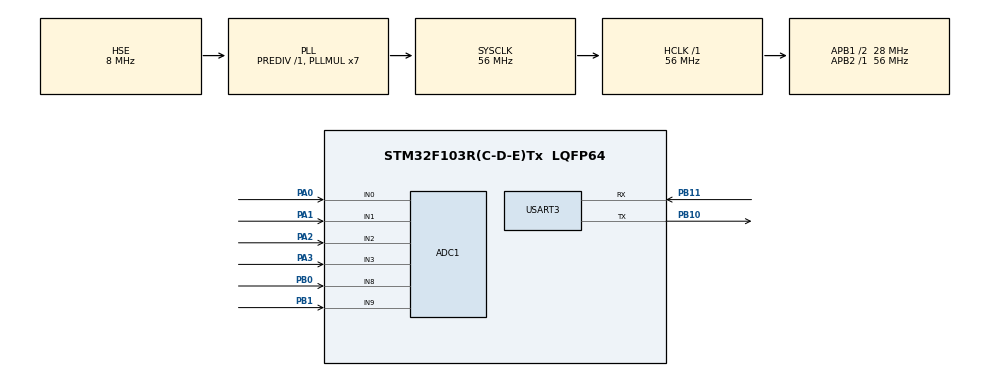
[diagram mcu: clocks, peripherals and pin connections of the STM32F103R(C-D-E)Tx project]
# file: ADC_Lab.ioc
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ADC1.Channel-0\#ChannelRegularConversion=ADC_CHANNEL_0
ADC1.ContinuousConvMode=ENABLE
ADC1.EnableAnalogWatchDog=false
ADC1.ExternalTrigConv=ADC_EXTERNALTRIGCONV_T3_TRGO
ADC1.NbrOfConversion=1
ADC1.NbrOfConversionFlag=1
ADC1.Rank-0\#ChannelRegularConversion=1
ADC1.SamplingTime-0\#ChannelRegularConversion=ADC_SAMPLETIME_1CYCLE_5
ADC1.master=1
Dma.ADC1.0.Direction=DMA_PERIPH_TO_MEMORY
Dma.ADC1.0.Instance=DMA1_Channel1
Dma.ADC1.0.MemDataAlignment=DMA_MDATAALIGN_WORD
Dma.ADC1.0.MemInc=DMA_MINC_ENABLE
Dma.ADC1.0.Mode=DMA_CIRCULAR
Dma.ADC1.0.PeriphDataAlignment=DMA_PDATAALIGN_WORD
Dma.ADC1.0.PeriphInc=DMA_PINC_DISABLE
Dma.ADC1.0.Priority=DMA_PRIORITY_LOW
Dma.Request0=ADC1
Mcu.Family=STM32F1
Mcu.Name=STM32F103R(C-D-E)Tx
Mcu.Package=LQFP64
NVIC.ADC1_2_IRQn=true\:0\:0\:false\:false\:true\:true\:true
NVIC.DMA1_Channel1_IRQn=true\:0\:0\:false\:false\:true\:false\:true
NVIC.PriorityGroup=NVIC_PRIORITYGROUP_4
NVIC.USART3_IRQn=true\:0\:0\:false\:false\:true\:true\:true
PA0-WKUP.Signal=ADCx_IN0
PA1.Signal=ADCx_IN1
PA13.Mode=Serial_Wire
PA13.Signal=SYS_JTMS-SWDIO
PA14.Mode=Serial_Wire
PA14.Signal=SYS_JTCK-SWCLK
PA2.Signal=ADCx_IN2
PA3.Signal=ADCx_IN3
PB0.Signal=ADCx_IN8
PB1.Signal=ADCx_IN9
PB10.Mode=Asynchronous
PB10.Signal=USART3_TX
PB11.Mode=Asynchronous
PB11.Signal=USART3_RX
PD0-OSC_IN.Mode=HSE-External-Oscillator
PD0-OSC_IN.Signal=RCC_OSC_IN
PD1-OSC_OUT.Mode=HSE-External-Oscillator
PD1-OSC_OUT.Signal=RCC_OSC_OUT
ProjectManager.HeapSize=0x300
ProjectManager.StackSize=0x400
ProjectManager.TargetToolchain=MDK-ARM V5
RCC.ADCPresc=RCC_ADCPCLK2_DIV4
RCC.AHBFreq_Value=56000000
RCC.APB1CLKDivider=RCC_HCLK_DIV2
RCC.APB1Freq_Value=28000000
RCC.APB1TimFreq_Value=56000000
RCC.APB2Freq_Value=56000000
RCC.APB2TimFreq_Value=56000000
RCC.HCLKFreq_Value=56000000
RCC.PLLMUL=RCC_PLL_MUL7
RCC.PLLSourceVirtual=RCC_PLLSOURCE_HSE
RCC.SYSCLKFreq_VALUE=56000000
RCC.SYSCLKSource=RCC_SYSCLKSOURCE_PLLCLK
RCC.USBFreq_Value=56000000
SH.ADCx_IN0.0=ADC1_IN0,IN0
SH.ADCx_IN1.0=ADC1_IN1,IN1
SH.ADCx_IN2.0=ADC1_IN2,IN2
SH.ADCx_IN3.0=ADC1_IN3,IN3
SH.ADCx_IN8.0=ADC1_IN8,IN8
SH.ADCx_IN9.0=ADC1_IN9,IN9
TIM3.AutoReloadPreload=TIM_AUTORELOAD_PRELOAD_ENABLE
TIM3.Period=10000-1
TIM3.Prescaler=56-1
TIM3.TIM_MasterOutputTrigger=TIM_TRGO_UPDATE
USART3.VirtualMode=VM_ASYNC
VP_TIM3_VS_ClockSourceINT.Mode=Internal
board=custom

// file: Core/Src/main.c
/* USER CODE BEGIN Header */
/**
  ******************************************************************************
  * @file           : main.c
  * @brief          : Main program body
  ******************************************************************************
  * @attention
  *
  * <h2><center>&copy; Copyright (c) 2021 STMicroelectronics.
  * All rights reserved.</center></h2>
  *
  * This software component is licensed by ST under BSD 3-Clause license,
  * the "License"; You may not use this file except in compliance with the
  * License. You may obtain a copy of the License at:
  *                        opensource.org/licenses/BSD-3-Clause
  *
  ******************************************************************************
  */
/* USER CODE END Header */
#include "main.h"

ADC_HandleTypeDef hadc1;
DMA_HandleTypeDef hdma_adc1;

TIM_HandleTypeDef htim3;

UART_HandleTypeDef huart3;

void SystemClock_Config(void);
static void MX_GPIO_Init(void);
static void MX_DMA_Init(void);
static void MX_ADC1_Init(void);
static void MX_USART3_UART_Init(void);
static void MX_TIM3_Init(void);
/* USER CODE BEGIN PFP */
uint32_t ADC_DR;
float Volt_mV;
/* USER CODE END PFP */

int main(void)
{

  /* MCU Configuration--------------------------------------------------------*/

  /* Reset of all peripherals, Initializes the Flash interface and the Systick. */
  HAL_Init();

  /* Configure the system clock */
  SystemClock_Config();

  /* Initialize all configured peripherals */
  MX_GPIO_Init();
  MX_DMA_Init();
  MX_ADC1_Init();
  MX_USART3_UART_Init();
  MX_TIM3_Init();
  /* USER CODE BEGIN 2 */
	HAL_TIM_Base_Start(&htim3);
	HAL_ADC_Start_DMA(&hadc1, &ADC_DR, 1);
  /* USER CODE END 2 */

  /* Infinite loop */
  while (1)
  {

    /* USER CODE BEGIN 3 */
		HAL_Delay(100);

  }
  /* USER CODE END 3 */
}

void SystemClock_Config(void)
{
  RCC_OscInitTypeDef RCC_OscInitStruct = {0};
  RCC_ClkInitTypeDef RCC_ClkInitStruct = {0};
  RCC_PeriphCLKInitTypeDef PeriphClkInit = {0};

  /** Initializes the RCC Oscillators according to the specified parameters
  * in the RCC_OscInitTypeDef structure.
  */
  RCC_OscInitStruct.OscillatorType = RCC_OSCILLATORTYPE_HSE;
  RCC_OscInitStruct.HSEState = RCC_HSE_ON;
  RCC_OscInitStruct.HSEPredivValue = RCC_HSE_PREDIV_DIV1;
  RCC_OscInitStruct.HSIState = RCC_HSI_ON;
  RCC_OscInitStruct.PLL.PLLState = RCC_PLL_ON;
  RCC_OscInitStruct.PLL.PLLSource = RCC_PLLSOURCE_HSE;
  RCC_OscInitStruct.PLL.PLLMUL = RCC_PLL_MUL7;
  if (HAL_RCC_OscConfig(&RCC_OscInitStruct) != HAL_OK)
  {
    Error_Handler();
  }
  /** Initializes the CPU, AHB and APB buses clocks
  */
  RCC_ClkInitStruct.ClockType = RCC_CLOCKTYPE_HCLK|RCC_CLOCKTYPE_SYSCLK
                              |RCC_CLOCKTYPE_PCLK1|RCC_CLOCKTYPE_PCLK2;
  RCC_ClkInitStruct.SYSCLKSource = RCC_SYSCLKSOURCE_PLLCLK;
  RCC_ClkInitStruct.AHBCLKDivider = RCC_SYSCLK_DIV1;
  RCC_ClkInitStruct.APB1CLKDivider = RCC_HCLK_DIV2;
  RCC_ClkInitStruct.APB2CLKDivider = RCC_HCLK_DIV1;

  if (HAL_RCC_ClockConfig(&RCC_ClkInitStruct, FLASH_LATENCY_2) != HAL_OK)
  {
    Error_Handler();
  }
  PeriphClkInit.PeriphClockSelection = RCC_PERIPHCLK_ADC;
  PeriphClkInit.AdcClockSelection = RCC_ADCPCLK2_DIV4;
  if (HAL_RCCEx_PeriphCLKConfig(&PeriphClkInit) != HAL_OK)
  {
    Error_Handler();
  }
}

static void MX_ADC1_Init(void)
{

  ADC_ChannelConfTypeDef sConfig = {0};

  /** Common config
  */
  hadc1.Instance = ADC1;
  hadc1.Init.ScanConvMode = ADC_SCAN_DISABLE;
  hadc1.Init.ContinuousConvMode = ENABLE;
  hadc1.Init.DiscontinuousConvMode = DISABLE;
  hadc1.Init.ExternalTrigConv = ADC_EXTERNALTRIGCONV_T3_TRGO;
  hadc1.Init.DataAlign = ADC_DATAALIGN_RIGHT;
  hadc1.Init.NbrOfConversion = 1;
  if (HAL_ADC_Init(&hadc1) != HAL_OK)
  {
    Error_Handler();
  }
  /** Configure Regular Channel
  */
  sConfig.Channel = ADC_CHANNEL_0;
  sConfig.Rank = ADC_REGULAR_RANK_1;
  sConfig.SamplingTime = ADC_SAMPLETIME_1CYCLE_5;
  if (HAL_ADC_ConfigChannel(&hadc1, &sConfig) != HAL_OK)
  {
    Error_Handler();
  }
  /* USER CODE BEGIN ADC1_Init 2 */
	HAL_ADCEx_Calibration_Start(&hadc1);
	HAL_Delay(10);
  /* USER CODE END ADC1_Init 2 */

}

static void MX_TIM3_Init(void)
{

  TIM_ClockConfigTypeDef sClockSourceConfig = {0};
  TIM_MasterConfigTypeDef sMasterConfig = {0};

  htim3.Instance = TIM3;
  htim3.Init.Prescaler = 56-1;
  htim3.Init.CounterMode = TIM_COUNTERMODE_UP;
  htim3.Init.Period = 10000-1;
  htim3.Init.ClockDivision = TIM_CLOCKDIVISION_DIV1;
  htim3.Init.AutoReloadPreload = TIM_AUTORELOAD_PRELOAD_ENABLE;
  if (HAL_TIM_Base_Init(&htim3) != HAL_OK)
  {
    Error_Handler();
  }
  sClockSourceConfig.ClockSource = TIM_CLOCKSOURCE_INTERNAL;
  if (HAL_TIM_ConfigClockSource(&htim3, &sClockSourceConfig) != HAL_OK)
  {
    Error_Handler();
  }
  sMasterConfig.MasterOutputTrigger = TIM_TRGO_UPDATE;
  sMasterConfig.MasterSlaveMode = TIM_MASTERSLAVEMODE_DISABLE;
  if (HAL_TIMEx_MasterConfigSynchronization(&htim3, &sMasterConfig) != HAL_OK)
  {
    Error_Handler();
  }

}

static void MX_USART3_UART_Init(void)
{

  huart3.Instance = USART3;
  huart3.Init.BaudRate = 115200;
  huart3.Init.WordLength = UART_WORDLENGTH_8B;
  huart3.Init.StopBits = UART_STOPBITS_1;
  huart3.Init.Parity = UART_PARITY_NONE;
  huart3.Init.Mode = UART_MODE_TX_RX;
  huart3.Init.HwFlowCtl = UART_HWCONTROL_NONE;
  huart3.Init.OverSampling = UART_OVERSAMPLING_16;
  if (HAL_UART_Init(&huart3) != HAL_OK)
  {
    Error_Handler();
  }

}

static void MX_DMA_Init(void)
{

  /* DMA controller clock enable */
  __HAL_RCC_DMA1_CLK_ENABLE();

  /* DMA interrupt init */
  /* DMA1_Channel1_IRQn interrupt configuration */
  HAL_NVIC_SetPriority(DMA1_Channel1_IRQn, 0, 0);
  HAL_NVIC_EnableIRQ(DMA1_Channel1_IRQn);

}

static void MX_GPIO_Init(void)
{

  /* GPIO Ports Clock Enable */
  __HAL_RCC_GPIOD_CLK_ENABLE();
  __HAL_RCC_GPIOA_CLK_ENABLE();
  __HAL_RCC_GPIOB_CLK_ENABLE();

}

/* USER CODE BEGIN 4 */
//void HAL_ADC_ConvHalfCpltCallback(ADC_HandleTypeDef* hadc)
//{
//
//  UNUSED(hadc);
//
//}
void HAL_ADC_ConvCpltCallback(ADC_HandleTypeDef* hadc)
{

  UNUSED(hadc);

	if(hadc->Instance == hadc1.Instance)
	{

	}
}
/* USER CODE END 4 */

void Error_Handler(void)
{
  __disable_irq();
  while (1)
  {
  }
}

/************************ (C) COPYRIGHT STMicroelectronics *****END OF FILE****/
